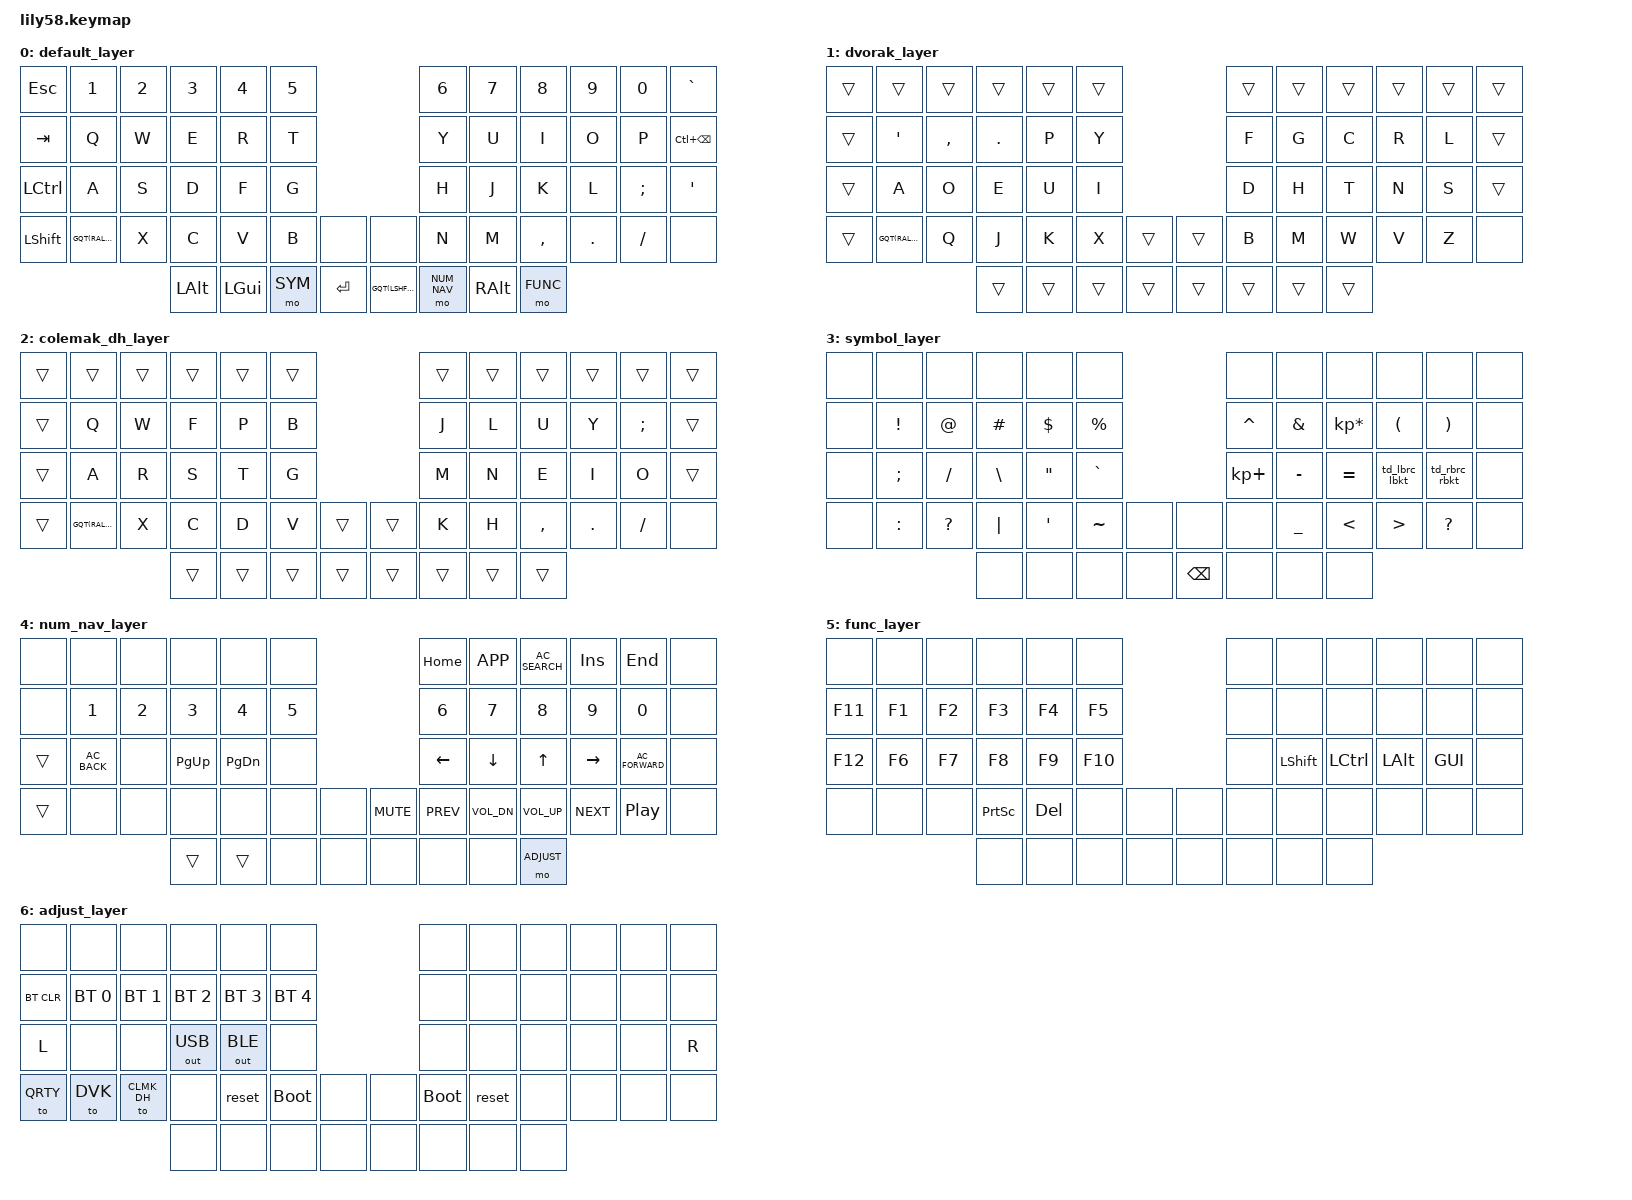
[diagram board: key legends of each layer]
/*
 * Copyright (c) 2020 The ZMK Contributors
 * Modified for Lily58 by Sohan Deshar
 *
 * SPDX-License-Identifier: MIT
 */

#include <behaviors.dtsi>
#include <dt-bindings/zmk/keys.h>
#include <dt-bindings/zmk/bt.h>
#include <dt-bindings/zmk/outputs.h>

#define QRTY 0
#define DVK 1
#define CLMK_DH 2
#define SYM 3
#define NUM_NAV 4
#define FUNC 5
#define ADJUST 6

#define _______________ &trans 
#define ______________X &none

// global quick tap
#define GQT(_hold, _tap) &gqt _hold _tap

// layer momentary toggle
#define LMT(_hold, _tog) &mo_tog _hold _tap

/{
	behaviors {
		mo_sk: momentary_sticky{
			compatible = "zmk,behavior-hold-tap";
			label = "momentary-sticky";
			#binding-cells = <2>;
			flavor = "hold-preferred";
			tapping-term-ms = <200>;
			bindings = <&mo>, <&sk>;
		};
		td_lbrc_lbkt: tap_dance_0 {
            compatible = "zmk,behavior-tap-dance";
            label = "LEFT_BRACE_BRACKET";
            #binding-cells = <0>;
            tapping-term-ms = <175>;
            bindings = <&kp LBRC>, <&kp LBKT>;
        };
		td_rbrc_rbkt: tap_dance_1 {
            compatible = "zmk,behavior-tap-dance";
            label = "RIGHT_BRACE_BRACKET";
            #binding-cells = <0>;
            tapping-term-ms = <175>;
            bindings = <&kp RBRC>, <&kp RBKT>;
        };
		td_bslh_pipe: tap_dance_2 {
            compatible = "zmk,behavior-tap-dance";
            label = "BSLH_PIPE";
            #binding-cells = <0>;
            tapping-term-ms = <180>;
            bindings = <&kp BSLH>, <&kp PIPE>;
        };
		td_dqt_sqt: tap_dance_3 {
            compatible = "zmk,behavior-tap-dance";
            label = "DQT_SQT";
            #binding-cells = <0>;
            tapping-term-ms = <180>;
            bindings = <&kp DQT>, <&kp SQT>;
        };
		td_eq_plus: tap_dance_4 {
            compatible = "zmk,behavior-tap-dance";
            label = "EQUAL_PLUS";
            #binding-cells = <0>;
            tapping-term-ms = <180>;
            bindings = <&kp EQUAL>, <&kp KP_PLUS>;
        };
		td_bt_td: tap_dance_5 {
            compatible = "zmk,behavior-tap-dance";
            label = "GRAVE_TILDE";
            #binding-cells = <0>;
            tapping-term-ms = <180>;
            bindings = <&kp GRAVE>, <&kp TILDE>;
        };
        ht: generic_hold_tap {
            compatible = "zmk,behavior-hold-tap";
            label = "HOLD_TAP";
            #binding-cells = <2>;
            flavor = "hold-preferred";
            tapping-term-ms = <200>;
            bindings = <&kp>, <&kp>;
        };
        mo_tog: layer_momentary_toggle {
            compatible = "zmk,behavior-hold-tap";
            label = "HOLD_TAP";
            #binding-cells = <2>;
            flavor = "hold-preferred";
            tapping-term-ms = <200>;
            bindings = <&mo>, <&tog>;
        };
        gqt: global-quick-tap {
            compatible = "zmk,behavior-hold-tap";
            label = "GLOBAL_QUICK_TAP";
            #binding-cells = <2>;
            flavor = "tap-preferred";
            tapping-term-ms = <200>;
            quick-tap-ms = <125>;
            global-quick-tap;
            bindings = <&kp>, <&kp>;
        };
	};
};

//
// |  0  1  2  3  4  5 |          |  6  7  8  9 10 11 |
// | 12 13 14 15 16 17 |          | 18 19 20 21 22 23 |
// | 24 25 26 27 28 29 |          | 30 31 32 33 34 35 |
// | 36 37 38 39 40 41 42 |    | 43 44 45 46 47 48 49 |
//          | 50 51 52 53 |    | 54 55 56 57 |
//

/ {
    combos {
        compatible = "zmk,combos";
        combo_esc_jk {
            timeout-ms = <100>;
            key-positions = <31 32>;
			layers = <0>;
            bindings = <&kp ESC>;
        };
        combo_esc_kj {
            timeout-ms = <100>;
            key-positions = <32 31>;
			layers = <0>;
            bindings = <&kp ESC>;
        };
    };
};

/ {
	keymap {
		compatible = "zmk,keymap";

//===================================================================================================================================================================================================================================
// Default Qwerty Layer
//----------------------

		default_layer {
//  * ,-------------------------------------------.                ,-------------------------------------------.
//  * |  ESC   |  1   |  2   |  3   |   4  |  5   |                |   6  |   7  |   8  |   9  |   0  |   `    |
//  * ,-------------------------------------------.                ,-------------------------------------------.
//  * |  TAB   |  Q   |  W   |  E   |   R  |  T   |                |   Y  |   U  |   I  |   O  |   P  |   <-   |
//  * |--------+------+------+------+------+------|                |------+------+------+------+------+--------|
//  * | LCTRL  |  A   |  S   |  D   |   F  |  G   |                |   H  |   J  |   K  |   L  |   ;  |   '    |
//  * |--------+------+------+------+------+------+------.  .------+------+------+------+------+------+--------|
//  * | LSHFT  |  Z   |  X   |  C   |   V  |  B   |      |  |      |   N  |   M  |   ,  |   .  |   /  |   XX   |
//  * `----------------------+------+------+------+------|  |------+------+------+------+----------------------'
//  *                        | LALT | GUI  | SYM  |  RET |  | LSHFT| NUM_ | RALT | FUNC |
//  *                        |      |      |      |      |  |SPACE | NAV  |      |      |
//  *                        `---------------------------'  `---------------------------'
			bindings = <
//_____________ _______________ _______________ _______________ _______________ _______________                                     _______________ _______________ _______________ _______________ _______________ _______________
&kp ESC         &kp N1          &kp N2          &kp N3          &kp N4          &kp N5                                              &kp N6          &kp N7          &kp N8          &kp N9          &kp N0          &kp GRAVE
&kp TAB         &kp Q           &kp W           &kp E           &kp R           &kp T                                               &kp Y           &kp U           &kp I           &kp O           &kp P           &kp LC(BSPC)
&kp LCTRL       &kp A           &kp S           &kp D           &kp F           &kp G                                               &kp H           &kp J           &kp K           &kp L           &kp SEMI        &kp SQT
&kp LSHFT       GQT(RALT,Z)     &kp X           &kp C           &kp V           &kp B           ______________X     ______________X &kp N           &kp M           &kp COMMA       &kp DOT         &kp FSLH        ______________X
//                                              _______________ _______________ _______________ _______________     _______________ _______________ _______________ _______________ 
                                                &kp LALT        &kp LGUI        &mo SYM         &kp RET             GQT(LSHFT,SPACE) &mo NUM_NAV    &kp RALT        &mo FUNC 
			>;

			sensor-bindings = <&inc_dec_kp C_VOL_UP C_VOL_DN>;
		};

//===================================================================================================================================================================================================================================
// Dvorak Layer
//---------------------

		dvorak_layer {
//  * ,-------------------------------------------.                ,-------------------------------------------.
//  * |        |      |      |      |      |      |                |      |      |      |      |      |        |
//  * ,-------------------------------------------.                ,-------------------------------------------.
//  * |        | ' "  | , <  | . >  |   P  |   Y  |                |   F  |   G  |   C  |   R  |   L  |        |
//  * |--------+------+------+------+------+------|                |------+------+------+------+------+--------|
//  * |        |  A   |   O  |  E   |   U  |  I   |                |   D  |   H  |   T  |   N  |   S  |        |
//  * |--------+------+------+------+------+------+------.  .------+------+------+------+------+------+--------|
//  * |        | ; :  |   Q  |  J   |   K  |  X   |      |  |      |   B  |   M  |   W  |   V  |   Z  |        |
//  * `----------------------+------+------+------+------|  |------+------+------+------+----------------------'
//  *                        |      |      |      |      |  |      |      |      |      |
//  *                        |      |      |      |      |  |      |      |      |      |
//  *                        `---------------------------'  `---------------------------'
			bindings = <
_______________ _______________ _______________ _______________ _______________ _______________                                     _______________ _______________ _______________ _______________ _______________ _______________
_______________ &kp SQT         &kp COMMA       &kp DOT         &kp P           &kp Y                                               &kp F           &kp G           &kp C           &kp R           &kp L           _______________
_______________ &kp A           &kp O           &kp E           &kp U           &kp I                                               &kp D           &kp H           &kp T           &kp N           &kp S           _______________
_______________ GQT(RALT,SEMI)  &kp Q           &kp J           &kp K           &kp X           _______________     _______________ &kp B           &kp M           &kp W           &kp V           &kp Z           ______________X
                                                _______________ _______________ _______________ _______________     _______________ _______________ _______________ _______________ 
			>;

			sensor-bindings = <&inc_dec_kp C_VOL_UP C_VOL_DN>;
		};

//===================================================================================================================================================================================================================================
// Colemak_DH layer
//-------------------------

        colemak_dh_layer {
   
//    Layer template
//    ,-------------------------------------------.                ,-------------------------------------------.
//    |        |      |      |      |      |      |                |      |      |      |      |      |        |
//    ,-------------------------------------------.                ,-------------------------------------------.
//    |        |  Q   |  W   |  F   |  P   |  B   |                |  J   |  L   |  U   |  Y   | ; :  |        |
//    |--------+------+------+------+------+------|                |------+------+------+------+------+--------|
//    |        |  A   |  R   |  S   |  T   |  G   |                |  M   |  N   |  E   |  I   |  O   |        |
//    |--------+------+------+------+------+------+------.  .------+------+------+------+------+------+--------|
//    |        |  Z   |  X   |  C   |  D   |  V   |      |  |      |  K   |  H   | , <  | . >  | / ?  |        |
//    `----------------------+------+------+------+------|  |------+------+------+------+----------------------'
//                           |      |      |      |      |  |      |      |      |      |
//                           |      |      |      |      |  |      |      |      |      |
//                           `---------------------------'  `---------------------------'
			bindings = <
_______________ _______________ _______________ _______________ _______________ _______________                                     _______________ _______________ _______________ _______________ _______________ _______________
_______________ &kp Q           &kp W           &kp F           &kp P           &kp B                                               &kp J           &kp L           &kp U           &kp Y           &kp SEMI        _______________
_______________ &kp A           &kp R           &kp S           &kp T           &kp G                                               &kp M           &kp N           &kp E           &kp I           &kp O           _______________
_______________ GQT(RALT,Z)     &kp X           &kp C           &kp D           &kp V           _______________     _______________ &kp K           &kp H           &kp COMMA       &kp DOT         &kp FSLH        ______________X
                                                _______________ _______________ _______________ _______________     _______________ _______________ _______________ _______________ 
			>;
		};





//===================================================================================================================================================================================================================================
// Symbol Layer
//---------------

		symbol_layer {
//    ,-------------------------------------------.                ,-------------------------------------------.
//    |        |      |      |      |      |      |                |      |      |      |      |      |        |
//    ,-------------------------------------------.                ,-------------------------------------------.
//    |        |  !   |  @   |  #   |  $   |  %   |                |  ^   |  &   |  *   |  (   |   )  |        |
//    |--------+------+------+------+------+------|                |------+------+------+------+------+--------|
//    |        |  ;   |  /   |  \   |  "   |  `   |                |  +   |   -  |  =   | {,[  |  },] |        |
//    |--------+------+------+------+------+------+------.  .------+------+------+------+------+------+--------|
//    |        |  :   |  ?   |  |   |  '   |  ~   |      |  |      |      |   _  |  <   |  >   |   ?  |        |
//    `----------------------+------+------+------+------|  |------+------+------+------+----------------------'
//                           |      |      |      |      |  | BSPC |      |      |      |
//                           |      |      |      |      |  |      |      |      |      |
//                           `---------------------------'  `---------------------------'
			bindings = <
______________X ______________X ______________X ______________X ______________X ______________X                                     ______________X ______________X ______________X ______________X ______________X ______________X
______________X &kp EXCL        &kp AT          &kp HASH        &kp DOLLAR      &kp PRCNT                                           &kp CARET       &kp AMPS        &kp KP_MULTIPLY &kp LPAR        &kp RPAR        ______________X
______________X &kp SEMI        &kp FSLH        &kp BSLH        &kp DQT         &kp GRAVE                                           &kp KP_PLUS     &kp MINUS       &kp EQUAL       &td_lbrc_lbkt   &td_rbrc_rbkt   ______________X
______________X &kp COLON       &kp QMARK       &kp PIPE        &kp SQT         &kp TILDE       ______________X     ______________X ______________X &kp UNDER       &kp LT          &kp GT          &kp QMARK       ______________X
                                                ______________X ______________X ______________X ______________X     &kp BSPC        ______________X ______________X ______________X
			>;

			sensor-bindings = <&inc_dec_kp C_VOL_UP C_VOL_DN>;
		};

//===================================================================================================================================================================================================================================
// NUM and Navigation Layer
//----------------------------
		num_nav_layer {
//    ,-------------------------------------------.                ,-------------------------------------------.
//    |        |      |      |      |      |      |                | HOME | MENU |SEARCH| INS  | END  |        |
//    ,-------------------------------------------.                ,-------------------------------------------.
//    |        |  1   |  2   |  3   |  4   |  5   |                |  6   |  7   |  8   |  9   |  0   |        |
//    |--------+------+------+------+------+------|                |------+------+------+------+------+--------|
//    |        | BACK |      | PG↑  | PG↓  |      |                |  ←   |  ↓   |   ↑  |  →   | FWD  |        |
//    |--------+------+------+------+------+------+------.  .------+------+------+------+------+------+--------|
//    |        |      |      |      |      |      |      |  | MUTE | PREV | VOL- | VOL+ | NEXT |  P/P |        |
//    `----------------------+------+------+------+------|  |------+------+------+------+----------------------'
//                           |      |      |      |      |  |      |      |      |ADJUST|
//                           |      |      |      |      |  |      |      |      |      |
//                           `---------------------------'  `---------------------------'
			bindings = <
//____________X ______________X ______________X ______________X ______________X ______________X                                      ______________X ______________X ______________X ______________X ______________X ______________X
______________X ______________X	______________X ______________X ______________X ______________X                                      &kp HOME        &kp K_APP       &kp C_AC_SEARCH &kp INS         &kp END         ______________X 
______________X &kp N1          &kp N2          &kp N3          &kp N4          &kp N5                                               &kp N6          &kp N7          &kp N8          &kp N9          &kp N0          ______________X 
_______________	&kp C_AC_BACK   ______________X &kp PG_UP       &kp PG_DN       ______________X                                      &kp LEFT        &kp DOWN        &kp UP          &kp RIGHT      &kp C_AC_FORWARD ______________X 
_______________ ______________X	______________X	______________X	______________X	______________X ______________X      &kp K_MUTE      &kp C_PREV      &kp C_VOL_DN    &kp C_VOL_UP    &kp C_NEXT      &kp C_PP        ______________X
                                                _______________ _______________ ______________X ______________X      ______________X ______________X ______________X &mo ADJUST 
			>;

			sensor-bindings = <&inc_dec_kp C_VOL_UP C_VOL_DN>;
		};
//===================================================================================================================================================================================================================================
// Function Layer
//---------------------

		func_layer {
//    ,-------------------------------------------.                ,-------------------------------------------.
//    |        |      |      |      |      |      |                |      |      |      |      |      |        |
//    ,-------------------------------------------.                ,-------------------------------------------.
//    |  F11   |  F1  |  F2  |  F3  |  F4  |  F5  |                |      |      |      |      |      |        |
//    |--------+------+------+------+------+------|                |------+------+------+------+------+--------|
//    |  F12   |  F6  |  F7  |  F8  |  F9  | F10  |                |      | SHFT | CTRL | ALT  | GUI  |        |
//    |--------+------+------+------+------+------+------.  .------+------+------+------+------+------+--------|
//    |        |      |      |PRSCR | DEL  |      |      |  |      |      |      |      |      |      |        |
//    `----------------------+------+------+------+------|  |------+------+------+------+----------------------'
//                           |      |      |      |      |  |      |      |      |      |
//                           |      |      |      |      |  |      |      |      |      |
//                           `---------------------------'  `---------------------------'
			bindings = <
______________X ______________X ______________X ______________X ______________X ______________X                                      ______________X ______________X ______________X ______________X ______________X ______________X
&kp F11         &kp F1          &kp F2          &kp F3          &kp F4          &kp F5                                               ______________X ______________X ______________X ______________X ______________X ______________X
&kp F12	        &kp F6          &kp F7          &kp F8          &kp F9          &kp F10                                              ______________X &kp LSHFT       &kp LCTRL       &kp LALT        &kp GUI         ______________X 
______________X ______________X	______________X &kp PSCRN       &kp DEL         ______________X ______________X      ______________X ______________X ______________X ______________X ______________X ______________X ______________X
                                                ______________X ______________X ______________X ______________X      ______________X ______________X ______________X ______________X 
			>;

			sensor-bindings = <&inc_dec_kp C_VOL_UP C_VOL_DN>;
		};

//===================================================================================================================================================================================================================================
// Adjust Layer
//-------------------

		adjust_layer {
//    ,-------------------------------------------.                ,-------------------------------------------.
//    |        |      |      |      |      |      |                |      |      |      |      |      |        |
//    ,-------------------------------------------.                ,-------------------------------------------.
//    | BTCLR  | BT1  | BT2  | BT3  | BT4  | BT5  |                |      |      |      |      |      |        |
//    |--------+------+------+------+------+------|                |------+------+------+------+------+--------|
//    |   L    |      |      |outUSB|outBLE|      |                |      |      |      |      |      |   R    | The L and R to check if this Layer is active or not to start the bootloader
//    |--------+------+------+------+------+------+------.  .------+------+------+------+------+------+--------|
//    |        | DVRK |CLMKDH|      |RESET |BTLDR |      |  |      |BTLDR |RESET |      |      |      |        |
//    `----------------------+------+------+------+------|  |------+------+------+------+----------------------'
//                           |      |      |      |      |  |      |      |      |      |
//                           |      |      |      |      |  |      |      |      |      |
//                           `---------------------------'  `---------------------------'
			bindings = <
______________X ______________X ______________X ______________X ______________X ______________X                                      ______________X ______________X ______________X ______________X ______________X ______________X
&bt BT_CLR      &bt BT_SEL 0    &bt BT_SEL 1    &bt BT_SEL 2    &bt BT_SEL 3    &bt BT_SEL 4                                         ______________X ______________X ______________X ______________X ______________X ______________X
&kp L           ______________X ______________X &out OUT_USB    &out OUT_BLE    ______________X                                      ______________X ______________X ______________X ______________X ______________X &kp R 
&to QRTY        &to DVK         &to CLMK_DH     ______________X &reset          &bootloader     ______________X      ______________X &bootloader     &reset          ______________X ______________X ______________X ______________X
                                                ______________X ______________X ______________X ______________X      ______________X ______________X ______________X ______________X
			>;

			sensor-bindings = <&inc_dec_kp C_VOL_UP C_VOL_DN>;
		}; 

//===================================================================================================================================================================================================================================

//    template_layer {
//   
//    Layer template
//    ,-------------------------------------------.                ,-------------------------------------------.
//    |        |      |      |      |      |      |                |      |      |      |      |      |        |
//    ,-------------------------------------------.                ,-------------------------------------------.
//    |        |      |      |      |      |      |                |      |      |      |      |      |        |
//    |--------+------+------+------+------+------|                |------+------+------+------+------+--------|
//    |        |      |      |      |      |      |                |      |      |      |      |      |        |
//    |--------+------+------+------+------+------+------.  .------+------+------+------+------+------+--------|
//    |        |      |      |      |      |      |      |  |      |      |      |      |      |      |        |
//    `----------------------+------+------+------+------|  |------+------+------+------+----------------------'
//                           |      |      |      |      |  |      |      |      |      |
//                           |      |      |      |      |  |      |      |      |      |
//                           `---------------------------'  `---------------------------'
//			bindings = <
//_______________ _______________ _______________ _______________ _______________ _______________                                      _______________ _______________ _______________ _______________ _______________ _______________
//_______________ _______________ _______________ _______________ _______________ _______________                                      _______________ _______________ _______________ _______________ _______________ _______________
//_______________ _______________ _______________ _______________ _______________ _______________                                      _______________ _______________ _______________ _______________ _______________ _______________
//_______________ _______________ _______________ _______________ _______________ _______________ _______________      _______________ _______________ _______________ _______________ _______________ _______________ _______________
//                                                _______________ _______________ _______________ _______________      _______________ _______________ _______________ _______________
//			>;
//
//			bindings = <
//______________X ______________X ______________X ______________X ______________X ______________X                                      ______________X ______________X ______________X ______________X ______________X ______________X
//______________X ______________X ______________X ______________X ______________X ______________X                                      ______________X ______________X ______________X ______________X ______________X ______________X
//______________X ______________X ______________X ______________X ______________X ______________X                                      ______________X ______________X ______________X ______________X ______________X ______________X
//______________X ______________X ______________X ______________X ______________X ______________X ______________X      ______________X ______________X ______________X ______________X ______________X ______________X ______________X
//                                                ______________X ______________X ______________X ______________X      ______________X ______________X ______________X ______________X
//			sensor-bindings = <&inc_dec_kp C_VOL_UP C_VOL_DN>;
//		};
	};
};
